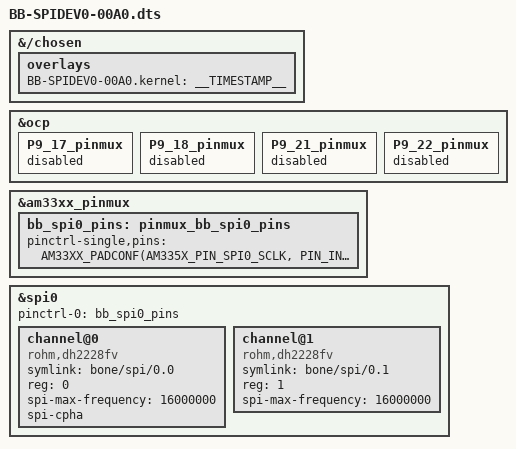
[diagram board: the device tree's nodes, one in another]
// SPDX-License-Identifier: GPL-2.0-only
/*
 * Copyright (C) 2013 CircuitCo
 * Virtual cape for SPI0 on connector pins P9.22 P9.21 P9.18 P9.17
 */

/dts-v1/;
/plugin/;

#include <dt-bindings/gpio/gpio.h>
#include <dt-bindings/pinctrl/am33xx.h>
#include <dt-bindings/interrupt-controller/irq.h>

/*
 * Helper to show loaded overlays under: /proc/device-tree/chosen/overlays/
 */
&{/chosen} {
	overlays {
		BB-SPIDEV0-00A0.kernel = __TIMESTAMP__;
	};
};

/*
 * Free up the pins used by the cape from the pinmux helpers.
 */
&ocp {
	P9_17_pinmux { status = "disabled"; };	/* P9_17 (A16) spi0_cs0.spi0_cs0 */
	P9_18_pinmux { status = "disabled"; };	/* P9_18 (B16) spi0_d1.spi0_d1 */
	P9_21_pinmux { status = "disabled"; };	/* P9_21 (B17) spi0_d0.spi0_d0 */
	P9_22_pinmux { status = "disabled"; };	/* P9_22 (A17) spi0_sclk.spi0_sclk */
};

&am33xx_pinmux {
	bb_spi0_pins: pinmux_bb_spi0_pins {
		pinctrl-single,pins = <
			AM33XX_PADCONF(AM335X_PIN_SPI0_SCLK, PIN_INPUT, MUX_MODE0)	/* P9_22 (A17) spi0_sclk.spi0_sclk */
			AM33XX_PADCONF(AM335X_PIN_SPI0_D0, PIN_INPUT, MUX_MODE0)	/* P9_21 (B17) spi0_d0.spi0_d0 */
			AM33XX_PADCONF(AM335X_PIN_SPI0_D1, PIN_INPUT, MUX_MODE0)	/* P9_18 (B16) spi0_d1.spi0_d1 */
			AM33XX_PADCONF(AM335X_PIN_SPI0_CS0, PIN_INPUT, MUX_MODE0)	/* P9_17 (A16) spi0_cs0.spi0_cs0 */
		>;
	};
};

&spi0 {
	#address-cells = <1>;
	#size-cells = <0>;

	status = "okay";
	pinctrl-names = "default";
	pinctrl-0 = <&bb_spi0_pins>;

	/*
	 * Select the D0 pin as output and D1 as
	 * input. The default is D0 as input and
	 * D1 as output.
	 */
	//ti,pindir-d0-out-d1-in;

	channel@0 {
		#address-cells = <1>;
		#size-cells = <0>;

		compatible = "rohm,dh2228fv";
		symlink = "bone/spi/0.0";

		reg = <0>;
		spi-max-frequency = <16000000>;
		spi-cpha;
	};

	channel@1 {
		#address-cells = <1>;
		#size-cells = <0>;

		compatible = "rohm,dh2228fv";
		symlink = "bone/spi/0.1";

		reg = <1>;
		spi-max-frequency = <16000000>;
	};
};
